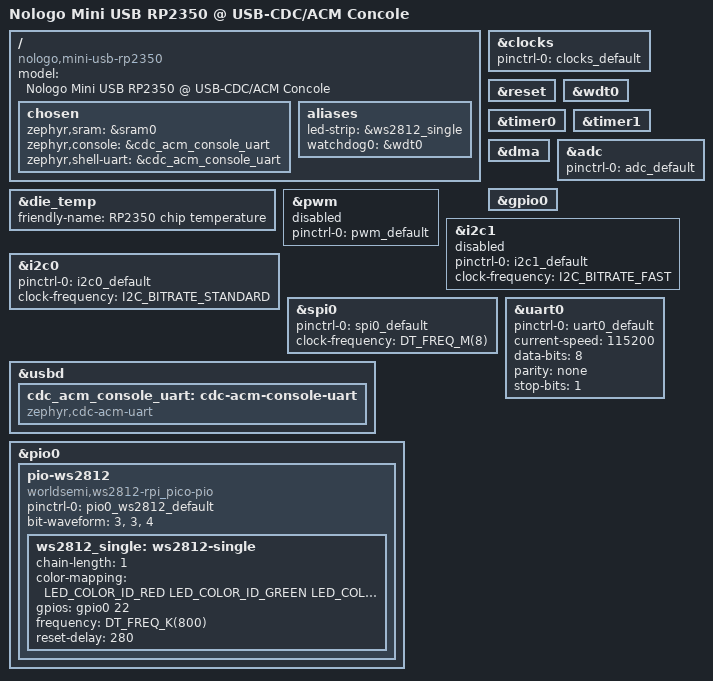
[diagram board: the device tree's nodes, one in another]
/*
 * Copyright (c) 2025 TiaC Systems
 * SPDX-License-Identifier: Apache-2.0
 */

/dts-v1/;

#include <freq.h>
#include <raspberrypi/rpi_pico/rp2350a.dtsi>
#include <raspberrypi/rpi_pico/m33.dtsi>
#include <zephyr/dt-bindings/regulator/rpi_pico.h>
#include <zephyr/dt-bindings/gpio/gpio.h>
#include <zephyr/dt-bindings/led/led.h>
#include <zephyr/dt-bindings/i2c/i2c.h>

#include "mini_usb_rp2350-pinctrl.dtsi"

#include "mini_usb_grove_connector.dtsi"
#include "mini_usb_connector.dtsi"
#include "mini_usb_pads.dtsi"

/ {
	model = "Nologo Mini USB RP2350 @ USB-CDC/ACM Concole";
	compatible = "nologo,mini-usb-rp2350", "nologo,mini-usb-rp2350-usbcons";

	chosen {
		zephyr,sram = &sram0;
		zephyr,console = &cdc_acm_console_uart;
		zephyr,shell-uart = &cdc_acm_console_uart;
	};

	aliases {
		led-strip = &ws2812_single;
		watchdog0 = &wdt0;
	};
};

&clocks {
	pinctrl-0 = <&clocks_default>;
	pinctrl-names = "default";
};

&reset {
	status = "okay";
};

&wdt0 {
	status = "okay";
};

&timer0 {
	status = "okay";
};

&timer1 {
	status = "okay";
};

&dma {
	status = "okay";
};

&adc {
	status = "okay";
	pinctrl-0 = <&adc_default>;
	pinctrl-names = "default";
};

&die_temp {
	status = "okay";
	friendly-name = "RP2350 chip temperature";
};

gpio0_lo: &gpio0 {
	status = "okay";
};

&pwm {
	status = "disabled";
	pinctrl-0 = <&pwm_default>;
	pinctrl-names = "default";
};

&i2c0 {
	status = "okay";
	pinctrl-0 = <&i2c0_default>;
	pinctrl-names = "default";
	clock-frequency = <I2C_BITRATE_STANDARD>;
};

&i2c1 {
	status = "disabled";
	pinctrl-0 = <&i2c1_default>;
	pinctrl-names = "default";
	clock-frequency = <I2C_BITRATE_FAST>;
};

&spi0 {
	status = "okay";
	pinctrl-0 = <&spi0_default>;
	pinctrl-names = "default";
	clock-frequency = <DT_FREQ_M(8)>;
};

&uart0 {
	status = "okay";
	pinctrl-0 = <&uart0_default>;
	pinctrl-names = "default";
	current-speed = <115200>;
	data-bits = <8>;
	parity = "none";
	stop-bits = "1";
};

zephyr_udc0: &usbd {
	status = "okay";
	cdc_acm_console_uart: cdc-acm-console-uart {
		compatible = "zephyr,cdc-acm-uart";
	};
};

&pio0 {
	status = "okay";
	pio-ws2812 {
		compatible = "worldsemi,ws2812-rpi_pico-pio";
		pinctrl-0 = <&pio0_ws2812_default>;
		pinctrl-names = "default";

		/* HI: 0x3F0: 1111110000: 0.750 us high and 0.500 us low */
		/* LO: 0x380: 1110000000: 0.375 us high and 0.875 us low */
		bit-waveform = <3>, <3>, <4>;

		ws2812_single: ws2812-single {
			chain-length = <1>;
			color-mapping = <LED_COLOR_ID_RED
					 LED_COLOR_ID_GREEN
					 LED_COLOR_ID_BLUE>;

			/* PIO0:OUT @ GP22 and Tbit = 1.25 us / 10 */
			gpios = <&gpio0 22 GPIO_ACTIVE_HIGH>;
			frequency = <DT_FREQ_K(800)>;
			reset-delay = <280>;
		};
	};
};
